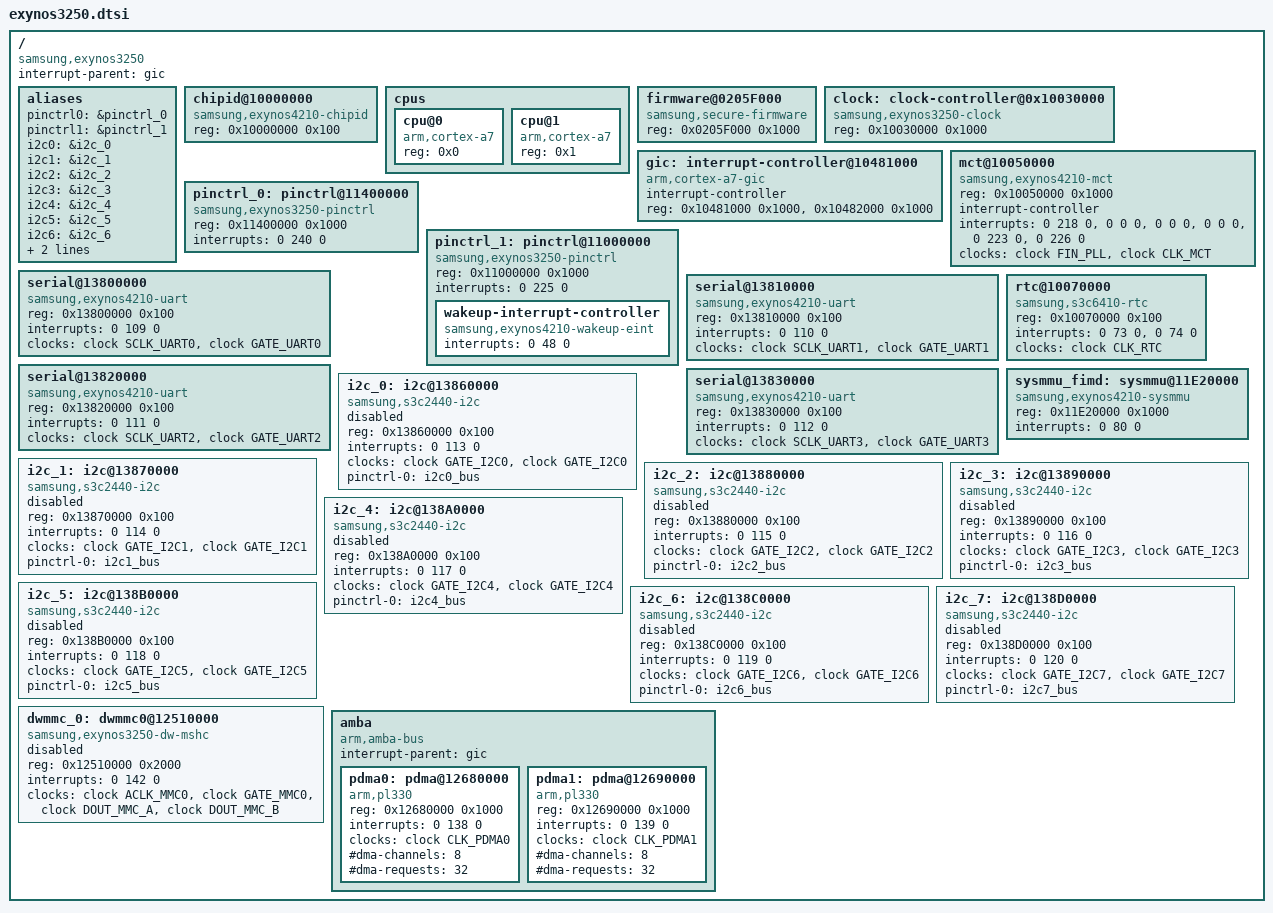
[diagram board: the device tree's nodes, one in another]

/*
 * SAMSUNG EXYNOS3250 SoC device tree source
 *
 * Copyright (c) 2014 Samsung Electronics Co., Ltd.
 *		http://www.samsung.com
 *
 * SAMSUNG EXYNOS3250 SoC device nodes are listed in this file.
 * EXYNOS3250 based board files can include this file and provide
 * values for board specfic bindings.
 *
 * This program is free software; you can redistribute it and/or modify
 * it under the terms of the GNU General Public License version 2 as
 * published by the Free Software Foundation.
 */

#include "skeleton.dtsi"
#include <dt-bindings/clk/exynos3250-clk.h>

/ {
	compatible = "samsung,exynos3250";

	interrupt-parent = <&gic>;

	aliases {
		pinctrl0 = &pinctrl_0;
                pinctrl1 = &pinctrl_1;
		i2c0 = &i2c_0;
		i2c1 = &i2c_1;
		i2c2 = &i2c_2;
		i2c3 = &i2c_3;
		i2c4 = &i2c_4;
		i2c5 = &i2c_5;
		i2c6 = &i2c_6;
		i2c7 = &i2c_7;
		mshc0 = &dwmmc_0;
	};

	chipid@10000000 {
		compatible = "samsung,exynos4210-chipid";
		reg = <0x10000000 0x100>;
	};

	cpus {
		#address-cells = <1>;
		#size-cells = <0>;

		cpu@0 {
			device_type = "cpu";
			compatible = "arm,cortex-a7";
			reg = <0x0>;
		};
		cpu@1 {
			device_type = "cpu";
			compatible = "arm,cortex-a7";
			reg = <0x1>;
		};
	};

	firmware@0205F000 {
		compatible = "samsung,secure-firmware";
		reg = <0x0205F000 0x1000>;
	};

	clock: clock-controller@0x10030000 {
		compatible = "samsung,exynos3250-clock";
		reg = <0x10030000 0x1000>;
		#clock-cells = <1>;
	};


	gic:interrupt-controller@10481000 {
		compatible = "arm,cortex-a7-gic";
		#interrupt-cells = <3>;
		interrupt-controller;
		reg =	<0x10481000 0x1000>,
			<0x10482000 0x1000>;
	};

	mct@10050000 {
		compatible = "samsung,exynos4210-mct";
		reg = <0x10050000 0x1000>;
		interrupt-controller;
		interrupts = <0 218 0> , <0 0 0>, <0 0 0>, <0 0 0>,
				<0 223 0>, <0 226 0>;
		clocks = <&clock FIN_PLL>, <&clock CLK_MCT>;
		clock-names = "fin_pll", "mct";
	};

	pinctrl_0: pinctrl@11400000 {
		compatible = "samsung,exynos3250-pinctrl";
		reg = <0x11400000 0x1000>;
		interrupts = <0 240 0>;
	};

	pinctrl_1: pinctrl@11000000 {
		compatible = "samsung,exynos3250-pinctrl";
		reg = <0x11000000 0x1000>;
		interrupts = <0 225 0>;

		wakeup-interrupt-controller {
			compatible = "samsung,exynos4210-wakeup-eint";
			interrupts = <0 48 0>;
		};
	};

	serial@13800000 {
		compatible = "samsung,exynos4210-uart";
		reg = <0x13800000 0x100>;
		interrupts = <0 109 0>;
		clocks = <&clock SCLK_UART0>, <&clock GATE_UART0>;
                clock-names = "sclk_uart0", "gate_uart0";
	};

	serial@13810000 {
		compatible = "samsung,exynos4210-uart";
		reg = <0x13810000 0x100>;
		interrupts = <0 110 0>;
		clocks = <&clock SCLK_UART1>, <&clock GATE_UART1>;
                clock-names = "sclk_uart1", "gate_uart1";
	};

	serial@13820000 {
		compatible = "samsung,exynos4210-uart";
		reg = <0x13820000 0x100>;
		interrupts = <0 111 0>;
		clocks = <&clock SCLK_UART2>, <&clock GATE_UART2>;
                clock-names = "sclk_uart2", "gate_uart2";
	};

	serial@13830000 {
		compatible = "samsung,exynos4210-uart";
		reg = <0x13830000 0x100>;
		interrupts = <0 112 0>;
		clocks = <&clock SCLK_UART3>, <&clock GATE_UART3>;
                clock-names = "sclk_uart3", "gate_uart3";
	};

	rtc@10070000 {
		compatible = "samsung,s3c6410-rtc";
		reg = <0x10070000 0x100>;
		interrupts = <0 73 0>, <0 74 0>;
		clocks = <&clock CLK_RTC>;
		clock-names = "rtc";
	};

	sysmmu_fimd: sysmmu@11E20000 {
		compatible = "samsung,exynos4210-sysmmu";
		reg = <0x11E20000 0x1000>;
		interrupts = <0 80 0>;
		/* mmu-masters = <&fimd>; */
	};

	i2c_0: i2c@13860000 {
		#address-cells = <1>;
		#size-cells = <0>;
		compatible = "samsung,s3c2440-i2c";
		reg = <0x13860000 0x100>;
		interrupts = <0 113 0>;
		clocks = <&clock GATE_I2C0>, <&clock GATE_I2C0>;
		clock-names = "rate_i2c", "gate_i2c";
		pinctrl-names = "default";
		pinctrl-0 = <&i2c0_bus>;
		status = "disabled";
	};

	i2c_1: i2c@13870000 {
		#address-cells = <1>;
		#size-cells = <0>;
		compatible = "samsung,s3c2440-i2c";
		reg = <0x13870000 0x100>;
		interrupts = <0 114 0>;
		clocks = <&clock GATE_I2C1>, <&clock GATE_I2C1>;
		clock-names = "rate_i2c", "gate_i2c";
		pinctrl-names = "default";
		pinctrl-0 = <&i2c1_bus>;
		status = "disabled";
	};

	i2c_2: i2c@13880000 {
		#address-cells = <1>;
		#size-cells = <0>;
		compatible = "samsung,s3c2440-i2c";
		reg = <0x13880000 0x100>;
		interrupts = <0 115 0>;
		clocks = <&clock GATE_I2C2>, <&clock GATE_I2C2>;
		clock-names = "rate_i2c", "gate_i2c";
		pinctrl-names = "default";
		pinctrl-0 = <&i2c2_bus>;
		status = "disabled";
	};

	i2c_3: i2c@13890000 {
		#address-cells = <1>;
		#size-cells = <0>;
		compatible = "samsung,s3c2440-i2c";
		reg = <0x13890000 0x100>;
		interrupts = <0 116 0>;
		clocks = <&clock GATE_I2C3>, <&clock GATE_I2C3>;
		clock-names = "rate_i2c", "gate_i2c";
		pinctrl-names = "default";
		pinctrl-0 = <&i2c3_bus>;
		status = "disabled";
	};

	i2c_4: i2c@138A0000 {
		#address-cells = <1>;
		#size-cells = <0>;
		compatible = "samsung,s3c2440-i2c";
		reg = <0x138A0000 0x100>;
		interrupts = <0 117 0>;
		clocks = <&clock GATE_I2C4>, <&clock GATE_I2C4>;
		clock-names = "rate_i2c", "gate_i2c";
		pinctrl-names = "default";
		pinctrl-0 = <&i2c4_bus>;
		status = "disabled";
	};

	i2c_5: i2c@138B0000 {
		#address-cells = <1>;
		#size-cells = <0>;
		compatible = "samsung,s3c2440-i2c";
		reg = <0x138B0000 0x100>;
		interrupts = <0 118 0>;
		clocks = <&clock GATE_I2C5>, <&clock GATE_I2C5>;
		clock-names = "rate_i2c", "gate_i2c";
		pinctrl-names = "default";
		pinctrl-0 = <&i2c5_bus>;
		status = "disabled";
	};

	i2c_6: i2c@138C0000 {
		#address-cells = <1>;
		#size-cells = <0>;
		compatible = "samsung,s3c2440-i2c";
		reg = <0x138C0000 0x100>;
		interrupts = <0 119 0>;
		clocks = <&clock GATE_I2C6>, <&clock GATE_I2C6>;
		clock-names = "rate_i2c", "gate_i2c";
		pinctrl-names = "default";
		pinctrl-0 = <&i2c6_bus>;
		status = "disabled";
	};

	i2c_7: i2c@138D0000 {
		#address-cells = <1>;
		#size-cells = <0>;
		compatible = "samsung,s3c2440-i2c";
		reg = <0x138D0000 0x100>;
		interrupts = <0 120 0>;
		clocks = <&clock GATE_I2C7>, <&clock GATE_I2C7>;
		clock-names = "rate_i2c", "gate_i2c";
		pinctrl-names = "default";
		pinctrl-0 = <&i2c7_bus>;
		status = "disabled";
	 };

	dwmmc_0: dwmmc0@12510000 {
		#address-cells = <1>;
                #size-cells = <0>;
		compatible = "samsung,exynos3250-dw-mshc";
		reg = <0x12510000 0x2000>;
		interrupts = <0 142 0>;
		clocks = <&clock ACLK_MMC0>, <&clock GATE_MMC0>, <&clock DOUT_MMC_A>, <&clock DOUT_MMC_B>;
		clock-names = "biu", "gate_ciu", "dout_mmc_a", "dout_mmc_b";
		status = "disabled";
	};

	amba {
		#address-cells = <1>;
		#size-cells = <1>;
		compatible = "arm,amba-bus";
		interrupt-parent = <&gic>;
		ranges;

		pdma0: pdma@12680000 {
			compatible = "arm,pl330", "arm,primecell";
			reg = <0x12680000 0x1000>;
			interrupts = <0 138 0>;
			clocks = <&clock CLK_PDMA0>;
			clock-names = "apb_pclk";
			#dma-cells = <1>;
			#dma-channels = <8>;
			#dma-requests = <32>;
		};

		pdma1: pdma@12690000 {
			compatible = "arm,pl330", "arm,primecell";
			reg = <0x12690000 0x1000>;
			interrupts = <0 139 0>;
			clocks = <&clock CLK_PDMA1>;
			clock-names = "apb_pclk";
			#dma-cells = <1>;
			#dma-channels = <8>;
			#dma-requests = <32>;
		};
	};
};

#include "exynos3250-pinctrl.dtsi"
